# DMASS_PKTDMA_0_DMASS_PKTDMA_0_PKTDMA_FLOW_48310000h register map
Vendor: Texas Instruments
Peripheral module from a debugger description file (folder am62L).
Registers are 32-bit, read-write, reset 0x0 unless marked. A register's access mark holds for its fields unless they carry their own. Offsets are as the file gives them; lines under a group give offsets from that group; [hi:lo] are bit positions; {n}, {i} and the like mark numbered series; 'fields as' and 'values as' point back to an identical list; <NAME> marks a mode.

## DMASS_PKTDMA_0_PKTDMA_FLOW
0x00 DMASS_PKTDMA_0_PKTDMA_FLOW_FLOW_resrc_j reset 0x80000000 — The Flow Resource Register contains the alias to real time register. A write to this register will reset the associated ring to clear the occupancies and reset the pointers.
  [31] ALIAS — Allow the Ring Address and Size Registers to appear in the Ring Real-Time region to allow for the ring to be placed and sized by the user process. Reset Source: rst_mod_g_rst_n
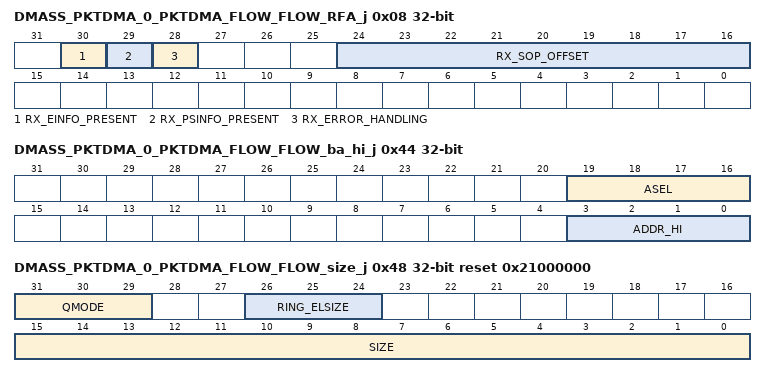
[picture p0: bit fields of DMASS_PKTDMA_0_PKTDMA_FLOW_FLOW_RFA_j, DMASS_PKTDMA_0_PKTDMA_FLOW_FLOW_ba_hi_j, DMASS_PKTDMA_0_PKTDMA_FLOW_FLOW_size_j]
0x08 DMASS_PKTDMA_0_PKTDMA_FLOW_FLOW_RFA_j — The Rx Flow N Configuration Register A contains static configuration information for the Rx DMA flow. The fields in this register can only be changed when all of the DMA channels that use this flow have been disabled. The fields in this register are as follows:
  [30] RX_EINFO_PRESENT — This bit controls whether or not the Extended Packet Info Block will be present in the Rx Packet Descriptor. If this bit is clear, the port DMA will clear the Extended Packet Info Present bit in the PD and will drop any Timestamp or SW Data words that are presented from the back end application. If this bit is set, the port DMA will set the Extended Packet Info Block Present bit in the PD and will copy any Timestamp or SW Data words that are presented across the Rx streaming interface into the Extended Packet Info Block words in the descriptor. If no Timestamp or SW Data words are presented from the back end application, the port DMA will overwrite the fields in the PD with zeroes. Reset Source: rst_mod_g_rst_n
  [29] RX_PSINFO_PRESENT — This bit controls whether or not the Protocol Specific words will be present in the Rx Packet Descriptor. If this bit is clear, the port DMA will set the PS word count to 0 in the PD and will drop any PS words that are presented from the back end application. If this bit is set, the port DMA will set the PS word count to the value given by the back end application and will copy the PS words from the back end application to the location Reset Source: rst_mod_g_rst_n
  [28] RX_ERROR_HANDLING — This bit controls the error handling mode for the flow and is only used when channel errors (i.e. descriptor starvation) occurs. 0 = Starvation errors result in dropping packet and incrementing dropped packet count. 1 = Starvation errors result in the channel waiting until descriptors are added to the free queue before the channel will be scheduled. Reset Source: rst_mod_g_rst_n
  [24:16] RX_SOP_OFFSET — This field specifies the number of bytes that are to be skipped in the SOP buffer before beginning to write the payload or protocol specific bytes(if they are in the sop buffer). This value must be less than the minimum size of a buffer in the system. Valid values are 0 - 255 bytes. The primary purpose of this field is to ensure that space is left in the descriptor to place the protocol specific information without overwriting or being overwritten by the Rx data. The secondary purpose of this field is to allow space to be left prior to the data in the descriptor in case header information needs to be added as the packet is passed thorough the system. Reset Source: rst_mod_g_rst_n
0x40 DMASS_PKTDMA_0_PKTDMA_FLOW_FLOW_ba_lo_j — The Ring Base Address Lo Register contains the 32 LSBs of the base address for the ring which is used to hand off pending work for the channel from the Host. The base address must be aligned to 0x8. A write to this register will reset the associated ring to clear the occupancies and reset the pointers.
  [31:0] ADDR_LO — Ring base address (LSBs) Reset Source: rst_mod_g_rst_n
0x44 DMASS_PKTDMA_0_PKTDMA_FLOW_FLOW_ba_hi_j — The Ring Base Address Hi Register contains the 16 MSBs of the base address for the ring which is used to hand off pending work for the channel from the Host. The base address must be aligned to 0x8. A write to this register will reset the associated ring to clear the occupancies and reset the pointers.
  [19:16] ASEL — Ring base address select Reset Source: rst_mod_g_rst_n
  [3:0] ADDR_HI — Ring base address (MSBs) Reset Source: rst_mod_g_rst_n
0x48 DMASS_PKTDMA_0_PKTDMA_FLOW_FLOW_size_j access not given reset 0x21000000 — The Ring Size Register contains the element count for the ring which is used to hand off pending work for the channel from the Host. A write to this register will reset the associated ring to clear the occupancies and reset the pointers.
  [31:29] QMODE — Defines the mode for this ring or queue. 1 exposed ring mode with dual queues (forward/reverse) for SW direct access (access R/NA)
  [26:24] RING_ELSIZE — This field is hardcode as 1 = 8 bytes. Reset Source: rst_mod_g_rst_n (access R/NA)
  [15:0] SIZE rw — This field configures the size of the ring in elements. Reset Source: rst_mod_g_rst_n
